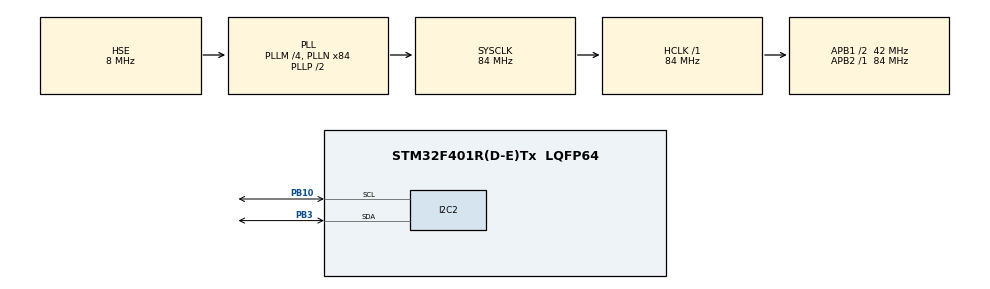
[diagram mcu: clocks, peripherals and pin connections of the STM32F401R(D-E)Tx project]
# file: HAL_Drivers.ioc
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FREERTOS.BinarySemaphores01=sem1,Dynamic,NULL
FREERTOS.INCLUDE_pcTaskGetTaskName=1
FREERTOS.INCLUDE_vTaskDelayUntil=1
FREERTOS.INCLUDE_xSemaphoreGetMutexHolder=1
FREERTOS.Queues01=queButton,16,uint16_t,0,Dynamic,NULL,NULL
FREERTOS.Tasks01=defaultTask,0,128,StartDefaultTask,Default,NULL,Dynamic,NULL,NULL;Led_Task,0,128,Led,Default,NULL,Dynamic,NULL,NULL;Button_Task,0,128,StartTask03,Default,NULL,Dynamic,NULL,NULL
FREERTOS.configENABLE_FPU=1
FREERTOS.configUSE_NEWLIB_REENTRANT=1
Mcu.Family=STM32F4
Mcu.Name=STM32F401R(D-E)Tx
Mcu.Package=LQFP64
NVIC.PriorityGroup=NVIC_PRIORITYGROUP_4
NVIC.TIM1_BRK_TIM9_IRQn=true\:15\:0\:false\:false\:true\:false\:false\:true
NVIC.TimeBase=TIM1_BRK_TIM9_IRQn
NVIC.TimeBaseIP=TIM9
PA13.Mode=Serial_Wire
PA13.Signal=SYS_JTMS-SWDIO
PA14.Mode=Serial_Wire
PA14.Signal=SYS_JTCK-SWCLK
PB10.Mode=I2C
PB10.Signal=I2C2_SCL
PB3.Mode=I2C
PB3.Signal=I2C2_SDA
PH0\ -\ OSC_IN.Mode=HSE-External-Clock-Source
PH0\ -\ OSC_IN.Signal=RCC_OSC_IN
PH1\ -\ OSC_OUT.Mode=HSE-External-Clock-Source
PH1\ -\ OSC_OUT.Signal=RCC_OSC_OUT
ProjectManager.HeapSize=0x800
ProjectManager.StackSize=0x400
ProjectManager.TargetToolchain=STM32CubeIDE
RCC.48MHZClocksFreq_Value=24000000
RCC.AHBFreq_Value=84000000
RCC.APB1CLKDivider=RCC_HCLK_DIV2
RCC.APB1Freq_Value=42000000
RCC.APB1TimFreq_Value=84000000
RCC.APB2Freq_Value=84000000
RCC.APB2TimFreq_Value=84000000
RCC.CortexFreq_Value=84000000
RCC.HCLKFreq_Value=84000000
RCC.HSE_VALUE=8000000
RCC.HSI_VALUE=16000000
RCC.PLLM=4
RCC.PLLN=84
RCC.PLLQ=7
RCC.PLLSourceVirtual=RCC_PLLSOURCE_HSE
RCC.RCC_MCO1Source=RCC_MCO1SOURCE_PLLCLK
RCC.SYSCLKFreq_VALUE=84000000
RCC.SYSCLKSource=RCC_SYSCLKSOURCE_PLLCLK
RCC.VCOOutputFreq_Value=168000000
VP_FREERTOS_VS_CMSIS_V1.Mode=CMSIS_V1
VP_SYS_VS_tim9.Mode=TIM9
board=NUCLEO-F401RE

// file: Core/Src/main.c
/* USER CODE BEGIN Header */
/**
  ******************************************************************************
  * @file           : main.c
  * @brief          : Main program body
  ******************************************************************************
  * @attention
  *
  * Copyright (c) 2022 STMicroelectronics.
  * All rights reserved.
  *
  * This software is licensed under terms that can be found in the LICENSE file
  * in the root directory of this software component.
  * If no LICENSE file comes with this software, it is provided AS-IS.
  *
  ******************************************************************************
  */
/* USER CODE END Header */
#include "main.h"
#include "cmsis_os.h"
#include "i2c.h"
#include "gpio.h"

/* USER CODE BEGIN Includes */
#include <stdio.h>
#include "stm32f4xx_nucleo.h"
/* USER CODE END Includes */

/* USER CODE BEGIN PD */

#define USE_SWV				0
/* USER CODE END PD */

/* USER CODE BEGIN PV */
uint8_t rxBuffer[100];
uint8_t txBuffer[100];
uint32_t len;
/* USER CODE END PV */

void SystemClock_Config(void);
void MX_FREERTOS_Init(void);

int main(void)
{

  /* MCU Configuration--------------------------------------------------------*/

  /* Reset of all peripherals, Initializes the Flash interface and the Systick. */
  HAL_Init();

  /* Configure the system clock */
  SystemClock_Config();

  /* Initialize all configured peripherals */
  MX_GPIO_Init();
  MX_I2C2_Init();
  /* USER CODE BEGIN 2 */
  //printf("ESCRIBA 5 DATOS->");
  DWT->CTRL |= 1;
  SEGGER_SYSVIEW_Conf();

  BSP_LED_Init(LED2);
  /* USER CODE END 2 */

  /* Call init function for freertos objects (in freertos.c) */
  MX_FREERTOS_Init();
  /* Start scheduler */
  osKernelStart();

  /* We should never get here as control is now taken by the scheduler */
  /* Infinite loop */
  while (1)
  {

    /* USER CODE BEGIN 3 */
	  HAL_GPIO_TogglePin(GPIOA, GPIO_PIN_5);
	  HAL_Delay(100);
  }
  /* USER CODE END 3 */
}

void SystemClock_Config(void)
{
  RCC_OscInitTypeDef RCC_OscInitStruct = {0};
  RCC_ClkInitTypeDef RCC_ClkInitStruct = {0};

  /** Configure the main internal regulator output voltage
  */
  __HAL_RCC_PWR_CLK_ENABLE();
  __HAL_PWR_VOLTAGESCALING_CONFIG(PWR_REGULATOR_VOLTAGE_SCALE2);
  /** Initializes the RCC Oscillators according to the specified parameters
  * in the RCC_OscInitTypeDef structure.
  */
  RCC_OscInitStruct.OscillatorType = RCC_OSCILLATORTYPE_HSE;
  RCC_OscInitStruct.HSEState = RCC_HSE_BYPASS;
  RCC_OscInitStruct.PLL.PLLState = RCC_PLL_ON;
  RCC_OscInitStruct.PLL.PLLSource = RCC_PLLSOURCE_HSE;
  RCC_OscInitStruct.PLL.PLLM = 4;
  RCC_OscInitStruct.PLL.PLLN = 84;
  RCC_OscInitStruct.PLL.PLLP = RCC_PLLP_DIV2;
  RCC_OscInitStruct.PLL.PLLQ = 7;
  if (HAL_RCC_OscConfig(&RCC_OscInitStruct) != HAL_OK)
  {
    Error_Handler();
  }
  /** Initializes the CPU, AHB and APB buses clocks
  */
  RCC_ClkInitStruct.ClockType = RCC_CLOCKTYPE_HCLK|RCC_CLOCKTYPE_SYSCLK
                              |RCC_CLOCKTYPE_PCLK1|RCC_CLOCKTYPE_PCLK2;
  RCC_ClkInitStruct.SYSCLKSource = RCC_SYSCLKSOURCE_PLLCLK;
  RCC_ClkInitStruct.AHBCLKDivider = RCC_SYSCLK_DIV1;
  RCC_ClkInitStruct.APB1CLKDivider = RCC_HCLK_DIV2;
  RCC_ClkInitStruct.APB2CLKDivider = RCC_HCLK_DIV1;

  if (HAL_RCC_ClockConfig(&RCC_ClkInitStruct, FLASH_LATENCY_2) != HAL_OK)
  {
    Error_Handler();
  }
}

/* USER CODE BEGIN 4 */

int __io_putchar(int ch){
#if (USE_SWV== 1)
	ITM_SendChar((uint32_t)ch);
#else
	uint8_t c = ch & 0xFF;
	while(!(USART2->SR & USART_SR_TXE));  //espera hasta que usart este listo para transmitir otro byte
	USART2->DR = c;
#endif
	return ch;
}

/* USER CODE END 4 */

void HAL_TIM_PeriodElapsedCallback(TIM_HandleTypeDef *htim)
{
  if (htim->Instance == TIM9) {
    HAL_IncTick();
  }
}

void Error_Handler(void)
{
  __disable_irq();
  while (1)
  {
  }
}

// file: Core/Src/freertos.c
/* USER CODE BEGIN Header */
/**
  ******************************************************************************
  * File Name          : freertos.c
  * Description        : Code for freertos applications
  ******************************************************************************
  * @attention
  *
  * Copyright (c) 2022 STMicroelectronics.
  * All rights reserved.
  *
  * This software is licensed under terms that can be found in the LICENSE file
  * in the root directory of this software component.
  * If no LICENSE file comes with this software, it is provided AS-IS.
  *
  ******************************************************************************
  */
/* USER CODE END Header */

#include "FreeRTOS.h"
#include "task.h"
#include "main.h"
#include "cmsis_os.h"

/* USER CODE BEGIN Includes */
#include "stm32f4xx_nucleo.h"
/* USER CODE END Includes */

osThreadId defaultTaskHandle;
osThreadId Led_TaskHandle;
osThreadId Button_TaskHandle;
osMessageQId queButtonHandle;
osSemaphoreId sem1Handle;

void StartDefaultTask(void const * argument);
void Led(void const * argument);
void StartTask03(void const * argument);

void MX_FREERTOS_Init(void); /* (MISRA C 2004 rule 8.1) */

/* GetIdleTaskMemory prototype (linked to static allocation support) */
void vApplicationGetIdleTaskMemory( StaticTask_t **ppxIdleTaskTCBBuffer, StackType_t **ppxIdleTaskStackBuffer, uint32_t *pulIdleTaskStackSize );

/* USER CODE BEGIN GET_IDLE_TASK_MEMORY */
static StaticTask_t xIdleTaskTCBBuffer;
static StackType_t xIdleStack[configMINIMAL_STACK_SIZE];

void vApplicationGetIdleTaskMemory( StaticTask_t **ppxIdleTaskTCBBuffer, StackType_t **ppxIdleTaskStackBuffer, uint32_t *pulIdleTaskStackSize )
{
  *ppxIdleTaskTCBBuffer = &xIdleTaskTCBBuffer;
  *ppxIdleTaskStackBuffer = &xIdleStack[0];
  *pulIdleTaskStackSize = configMINIMAL_STACK_SIZE;
  /* place for user code */
}
/* USER CODE END GET_IDLE_TASK_MEMORY */

void MX_FREERTOS_Init(void) {

  /* Create the semaphores(s) */
  /* definition and creation of sem1 */
  osSemaphoreDef(sem1);
  sem1Handle = osSemaphoreCreate(osSemaphore(sem1), 1);

  /* Create the queue(s) */
  /* definition and creation of queButton */
  osMessageQDef(queButton, 16, uint16_t);
  queButtonHandle = osMessageCreate(osMessageQ(queButton), NULL);

  /* Create the thread(s) */
  /* definition and creation of defaultTask */
  osThreadDef(defaultTask, StartDefaultTask, osPriorityNormal, 0, 128);
  defaultTaskHandle = osThreadCreate(osThread(defaultTask), NULL);

  /* definition and creation of Led_Task */
  osThreadDef(Led_Task, Led, osPriorityNormal, 0, 128);
  Led_TaskHandle = osThreadCreate(osThread(Led_Task), NULL);

  /* definition and creation of Button_Task */
  osThreadDef(Button_Task, StartTask03, osPriorityNormal, 0, 128);
  Button_TaskHandle = osThreadCreate(osThread(Button_Task), NULL);

}

void StartDefaultTask(void const * argument)
{
  /* USER CODE BEGIN StartDefaultTask */
  /* Infinite loop */
  for(;;)
  {
	  SEGGER_SYSVIEW_PrintfTarget("mensaje de tarea por defecto%u\n",100);
	  osDelay(40);
  }
  /* USER CODE END StartDefaultTask */
}

void Led(void const * argument)
{
  /* USER CODE BEGIN Led */
  /* Infinite loop */
  for(;;)
  {
	  BSP_LED_Toggle(LED2);
	  SEGGER_SYSVIEW_PrintfTarget("mensaje de led%u\n",1);
	  osDelay(1000);
  }
  /* USER CODE END Led */
}

void StartTask03(void const * argument)
{
  /* USER CODE BEGIN StartTask03 */
  /* Infinite loop */
  for(;;)
  {
	  SEGGER_SYSVIEW_PrintfTarget("mensaje de task%u\n",3);
	  osDelay(100);
  }
  /* USER CODE END StartTask03 */
}
